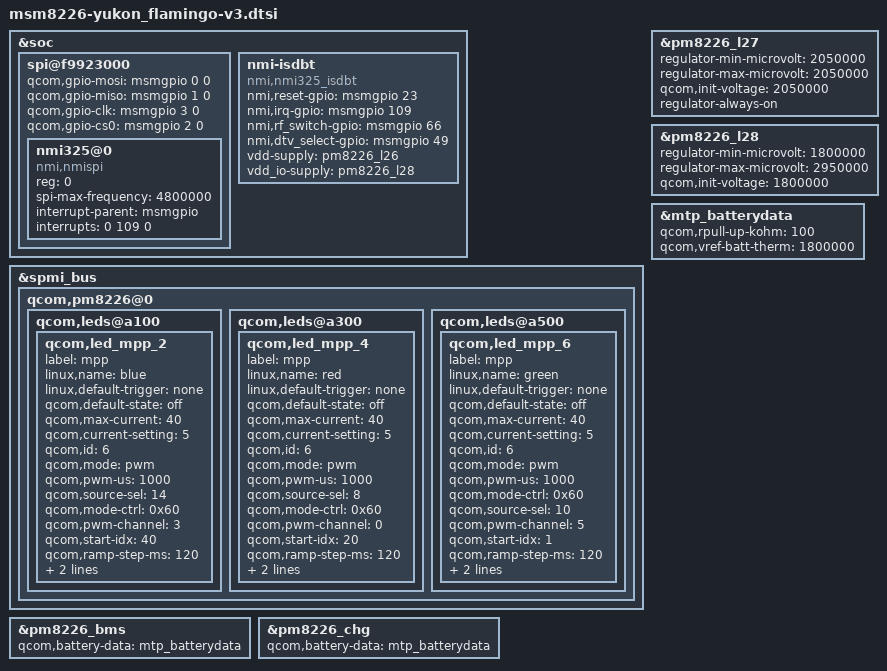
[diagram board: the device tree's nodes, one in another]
/include/ "msm8226-yukon_flamingo-v2.dtsi"

&soc {
	spi@f9923000 {
		qcom,gpio-mosi = <&msmgpio 0 0>;
		qcom,gpio-miso = <&msmgpio 1 0>;
		qcom,gpio-clk  = <&msmgpio 3 0>;
		qcom,gpio-cs0  = <&msmgpio 2 0>;
		nmi325@0 {
			compatible = "nmi,nmispi"; 
			reg = <0>; 
			spi-max-frequency = <4800000>;
			interrupt-parent = <&msmgpio>;
			interrupts = <0 109 0>;	
		};
	};

	nmi-isdbt {
		compatible = "nmi,nmi325_isdbt";
		nmi,reset-gpio = <&msmgpio 23 0x00>;
		nmi,irq-gpio = <&msmgpio 109 0x2008>;
		nmi,rf_switch-gpio = <&msmgpio 66 0x00>;
		nmi,dtv_select-gpio = <&msmgpio 49 0x00>;
		vdd-supply = <&pm8226_l26>;
		vdd_io-supply = <&pm8226_l28>;
	};
};

&spmi_bus {
	qcom,pm8226@0 {
		qcom,leds@a100 {
			status = "okay";
			qcom,led_mpp_2 {
				label = "mpp";
				linux,name = "blue";
				linux,default-trigger = "none";
				qcom,default-state = "off";
				qcom,max-current = <40>;
				qcom,current-setting = <5>;
				qcom,id = <6>;
				qcom,mode = "pwm";
				qcom,pwm-us = <1000>;
				qcom,source-sel = <14>;
				qcom,mode-ctrl = <0x60>;
				qcom,pwm-channel = <3>;
				qcom,start-idx = <40>;
				qcom,ramp-step-ms = <120>;
				qcom,duty-pcts = [00 00 50 99 99 99 50 00];
				qcom,use-blink;
			};
		};

		qcom,leds@a300 {
			status = "okay";
			qcom,led_mpp_4 {
				label = "mpp";
				linux,name = "red";
				linux,default-trigger = "none";
				qcom,default-state = "off";
				qcom,max-current = <40>;
				qcom,current-setting = <5>;
				qcom,id = <6>;
				qcom,mode = "pwm";
				qcom,pwm-us = <1000>;
				qcom,source-sel = <8>;
				qcom,mode-ctrl = <0x60>;
				qcom,pwm-channel = <0>;
				qcom,start-idx = <20>;
				qcom,ramp-step-ms = <120>;
				qcom,duty-pcts = [00 00 50 99 99 99 50 00];
				qcom,use-blink;
			};
		};

		qcom,leds@a500 {
			status = "okay";
			qcom,led_mpp_6 {
				label = "mpp";
				linux,name = "green";
				linux,default-trigger = "none";
				qcom,default-state = "off";
				qcom,max-current = <40>;
				qcom,current-setting = <5>;
				qcom,id = <6>;
				qcom,mode = "pwm";
				qcom,pwm-us = <1000>;
				qcom,mode-ctrl = <0x60>;
				qcom,source-sel = <10>;
				qcom,pwm-channel = <5>;
				qcom,start-idx = <1>;
				qcom,ramp-step-ms = <120>;
				qcom,duty-pcts = [00 00 50 99 99 99 50 00];
				qcom,use-blink;
			};
		};
	};
};

&pm8226_l27{
	regulator-min-microvolt = <2050000>;
	regulator-max-microvolt = <2050000>;
	qcom,init-voltage = <2050000>;
	regulator-always-on;
};

&pm8226_l28{
	regulator-min-microvolt = <1800000>;
	regulator-max-microvolt = <2950000>;
	qcom,init-voltage = <1800000>;
};

&mtp_batterydata {
	qcom,rpull-up-kohm = <100>;
	qcom,vref-batt-therm = <1800000>;
	/include/ "batterydata-yukon_flamingo.dtsi"
};

&pm8226_bms {
	qcom,battery-data = <&mtp_batterydata>;
};

&pm8226_chg {
	qcom,battery-data = <&mtp_batterydata>;
};
